# STM32U031 register map
File version: 1.0
CPU: CM0+ r0p1, little endian, MPU, no FPU, 4 interrupt priority bits
Registers are 32-bit, read-write, reset 0x0 unless marked. A register's access mark holds for its fields unless they carry their own. Offsets are from the block's base; [hi:lo] are bit positions.

## FLASH — Mamba FLASH register block
Base 0x40022000
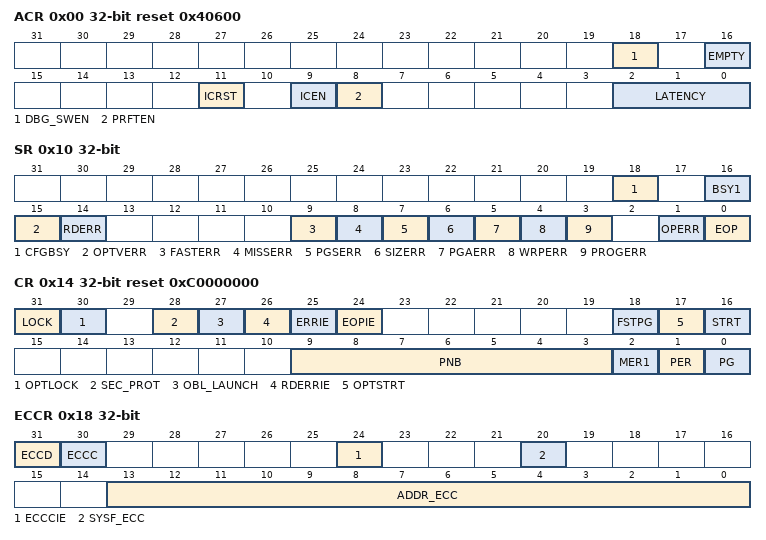
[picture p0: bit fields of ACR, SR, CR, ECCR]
0x00 ACR reset 0x40600 — FLASH access control register
  [18] DBG_SWEN — Debug access software enable Software may use this bit to enable/disable the debugger read access.
  [16] EMPTY — Main flash memory area empty This bit indicates whether the first location of the main flash memory area is erased or has a programmed value. The bit can be set and reset by software.
  [11] ICRST — CPU Instruction cache reset This bit can be written only when the instruction cache is disabled.
  [9] ICEN — CPU Instruction cache enable
  [8] PRFTEN — CPU Prefetch enable
  [2:0] LATENCY — Flash memory access latency The value in this bitfield represents the number of CPU wait states when accessing the flash memory. Other: Reserved A new write into the bitfield becomes effective when it returns the same value upon read.
0x08 KEYR wo — FLASH key register
  [31:0] KEY — FLASH key The following values must be written consecutively to unlock the FLASH control register (FLASH_CR), thus enabling programming/erasing operations: KEY1: 0x4567 0123 KEY2: 0xCDEF 89AB
0x0C OPTKEYR wo — FLASH option key register
  [31:0] OPTKEY — Option byte key The following values must be written consecutively to unlock the flash memory option registers, enabling option byte programming/erasing operations: KEY1: 0x0819 2A3B KEY2: 0x4C5D 6E7F
0x10 SR access per field (reset mask 0xFFF0FFFF) — FLASH status register
  [18] CFGBSY ro — Programming or erase configuration busy. This flag is set and cleared by hardware. It is set when the first word is sent for program or when setting the STRT bit of FLASH control register (FLASH_CR) for erase. It is cleared when the flash memory program or erase operation completes or ends with an error. When set, launching any other operation through the FLASH control register (FLASH_CR) is impossible, and must be postponed (a programming or erase operation is ongoing). When cleared, the program and erase settings in the FLASH control register (FLASH_CR) can be modified.
  [16] BSY1 ro — Busy This flag indicates that a flash memory operation requested by FLASH control register (FLASH_CR) is in progress. This bit is set at the beginning of the flash memory operation, and cleared when the operation finishes or when an error occurs.
  [15] OPTVERR rw — Option and Engineering bits loading validity error
  [14] RDERR rw — PCROP read error Set by hardware when an address to be read belongs to a read protected area of the flash memory (PCROP protection). An interrupt is generated if RDERRIE is set in FLASH_CR. Cleared by writing 1.
  [9] FASTERR rw — Fast programming error Set by hardware when a fast programming sequence (activated by FSTPG) is interrupted due to an error (alignment, size, write protection or data miss). The corresponding status bit (PGAERR, SIZERR, WRPERR or MISSERR) is set at the same time. Cleared by writing 1.
  [8] MISSERR rw — Fast programming data miss error In Fast programming mode, 16 double words (128 bytes) must be sent to flash memory successively, and the new data must be sent to the logic control before the current data is fully programmed. MISSERR is set by hardware when the new data is not present in time. Cleared by writing 1.
  [7] PGSERR rw — Programming sequence error Set by hardware when a write access to the flash memory is performed by the code while PG or FSTPG have not been set previously. Set also by hardware when PROGERR, SIZERR, PGAERR, WRPERR, MISSERR or FASTERR is set due to a previous programming error. Cleared by writing 1.
  [6] SIZERR rw — Size error Set by hardware when the size of the access is a byte or half-word during a program or a fast program sequence. Only double word programming is allowed (consequently: word access). Cleared by writing 1.
  [5] PGAERR rw — Programming alignment error Set by hardware when the data to program cannot be contained in the same double word (64-bit) flash memory in case of standard programming, or if there is a change of page during fast programming. Cleared by writing 1.
  [4] WRPERR rw — Write protection error Set by hardware when an address to be erased/programmed belongs to a write-protected part (by WRP, PCROP or RDP Level 1) of the flash memory. Cleared by writing 1.
  [3] PROGERR rw — Programming error Set by hardware when a double-word address to be programmed contains a value different from '0xFFFF FFFF' before programming, except if the data to write is '0x0000 0000'. Cleared by writing 1.
  [1] OPERR rw — Operation error Set by hardware when a flash memory operation (program / erase) completes unsuccessfully. This bit is set only if error interrupts are enabled (ERRIE=1). Cleared by writing 1.
  [0] EOP rw — End of operation Set by hardware when one or more flash memory operation (programming / erase) has been completed successfully. This bit is set only if the end of operation interrupts are enabled (EOPIE=1). Cleared by writing 1.
0x14 CR reset 0xC0000000 — FLASH control register
  [31] LOCK — FLASH_CR Lock This bit is set only. When set, the FLASH_CR register is locked. It is cleared by hardware after detecting the unlock sequence. In case of an unsuccessful unlock operation, this bit remains set until the next system reset.
  [30] OPTLOCK — Options Lock This bit is set only. When set, all bits concerning user option in FLASH_CR register and so option page are locked. This bit is cleared by hardware after detecting the unlock sequence. The LOCK bit must be cleared before doing the unlock sequence for OPTLOCK bit. In case of an unsuccessful unlock operation, this bit remains set until the next reset.
  [28] SEC_PROT — Securable memory area protection enable This bit enables the protection on securable area, provided that a non-null securable memory area size (SEC_SIZE[4:0]) is defined in option bytes. This bit is possible to set only by software and to clear only through a system reset.
  [27] OBL_LAUNCH — Option byte load launch When set, this bit triggers the load of option bytes into option registers. It is automatically cleared upon the completion of the load. The high state of the bit indicates pending option byte load. The bit cannot be cleared by software. It cannot be written as long as OPTLOCK is set.
  [26] RDERRIE — PCROP read error interrupt enable This bit enables the interrupt generation upon setting the RDERR flag in the FLASH_SR register.
  [25] ERRIE — Error interrupt enable This bit enables the interrupt generation upon setting the OPERR flag in the FLASH_SR register.
  [24] EOPIE — End-of-operation interrupt enable This bit enables the interrupt generation upon setting the EOP flag in the FLASH_SR register.
  [18] FSTPG — Fast programming enable
  [17] OPTSTRT — Start of modification of option bytes This bit triggers an options operation when set. This bit is set only by software, and is cleared when the BSY1 bit is cleared in FLASH_SR.
  [16] STRT — Start erase operation This bit triggers an erase operation when set. This bit is possible to set only by software and to clear only by hardware. The hardware clears it when one of BSY1 and BSY2 flags in the FLASH_SR register transits to zero.
  [9:3] PNB — Page number selection These bits select the page to erase: ... Note: Values corresponding to addresses outside the main memory are not allowed.
  [2] MER1 — Mass erase When set, this bit triggers the mass erase, that is, all user pages.
  [1] PER — Page erase enable
  [0] PG — Flash memory programming enable
0x18 ECCR access per field — FLASH ECC register
  [31] ECCD rw — ECC detection Set by hardware when two ECC errors have been detected. When this bit is set, a NMI is generated. Cleared by writing 1.
  [30] ECCC rw — ECC correction Set by hardware when one ECC error has been detected and corrected. An interrupt is generated if ECCIE is set. Cleared by writing 1.
  [24] ECCCIE rw — ECC correction interrupt enable
  [20] SYSF_ECC ro — System Flash memory ECC fail This bit indicates that the ECC error correction or double ECC error detection is located in the system Flash memory.
  [13:0] ADDR_ECC ro — ECC fail double-word address offset In case of ECC error or ECC correction detected, this bitfield contains double-word offset (multiple of 64 bits) to main Flash memory.
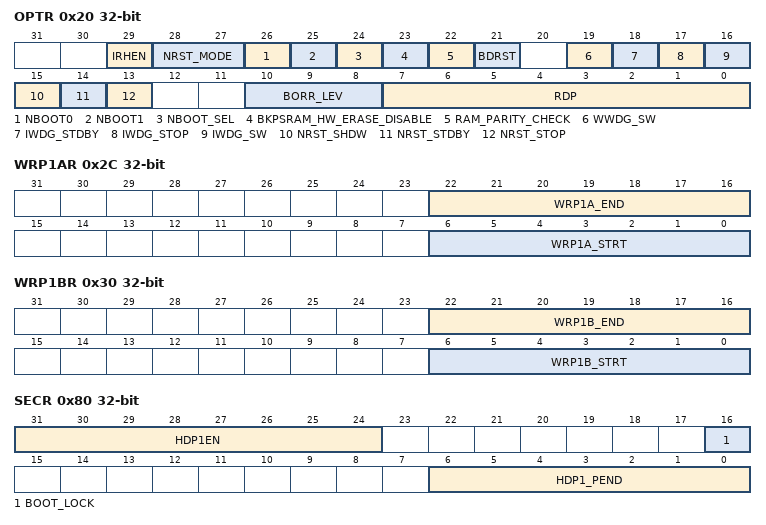
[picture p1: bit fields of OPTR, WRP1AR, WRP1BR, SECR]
0x20 OPTR reset not defined — FLASH option register
  [29] IRHEN — Internal reset holder enable bit
  [28:27] NRST_MODE — NRST pin configuration
  [26] NBOOT0 — NBOOT0 option bit
  [25] NBOOT1 — Boot configuration Together with the BOOT0 pin or option bit NBOOT0 (depending on NBOOT_SEL option bit configuration), this bit selects boot mode from the main flash memory, SRAM or the system memory. Refer to Section12.5: Boot configuration.
  [24] NBOOT_SEL — BOOT0 signal source selection This option bit defines the source of the BOOT0 signal.
  [23] BKPSRAM_HW_ERASE_DISABLE — Backup SRAM erase prevention
  [22] RAM_PARITY_CHECK — SRAM parity check control enable/disable
  [21] BDRST — Backup domain reset
  [19] WWDG_SW — Window watchdog selection
  [18] IWDG_STDBY — Independent watchdog counter freeze in Standby mode
  [17] IWDG_STOP — Independent watchdog counter freeze in Stop mode
  [16] IWDG_SW — Independent watchdog selection
  [15] NRST_SHDW — Reset generated when entering Shutdown mode
  [14] NRST_STDBY — Reset generated when entering Standby mode
  [13] NRST_STOP — Reset generated when entering Stop mode
  [10:8] BORR_LEV — BOR reset level
  [7:0] RDP — Read protection level Other: Level 1, memories read protection active
0x2C WRP1AR (reset mask 0xFFF0FFF0) — FLASH WRP area A address register
  [22:16] WRP1A_END — WRP area A end offset This bitfield contains the offset of the last page of the WRP area A. Note: The number of effective bits depends on the size of the flash memory in the device.
  [6:0] WRP1A_STRT — WRP area A start offset This bitfield contains the offset of the first page of the WRP area A. Note: The number of effective bits depends on the size of the flash memory in the device.
0x30 WRP1BR (reset mask 0xFFF0FFF0) — FLASH WRP area B address register
  [22:16] WRP1B_END — WRP area B end offset This bitfield contains the offset of the last page of the WRP area B. Note: The number of effective bits depends on the size of the flash memory in the device.
  [6:0] WRP1B_STRT — WRP area B start offset This bitfield contains the offset of the first page of the WRP area B. Note: The number of effective bits depends on the size of the flash memory in the device.
0x80 SECR (reset mask 0xFFFEFFE0) — FLASH security register
  [31:24] HDP1EN — Hide protection area enable
  [16] BOOT_LOCK — used to force boot from user area If the bit is set in association with RDP level 1, the debug capabilities are disabled, except in the case of a bad OBL (mismatch).
  [6:0] HDP1_PEND — Last page of the first hide protection area
